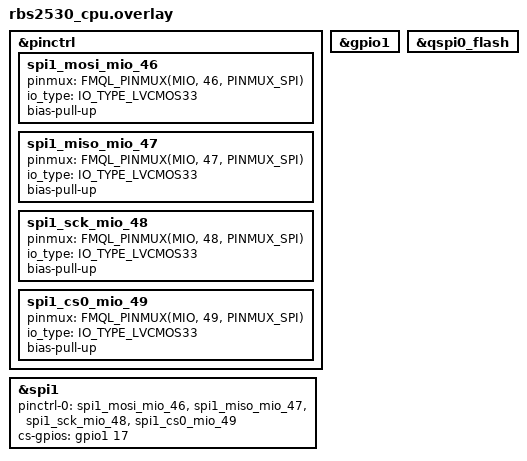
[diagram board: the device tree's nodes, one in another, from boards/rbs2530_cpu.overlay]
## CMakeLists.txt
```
# SPDX-License-Identifier: Apache-2.0

cmake_minimum_required(VERSION 3.20.0)

find_package(Zephyr REQUIRED HINTS $ENV{ZEPHYR_BASE})
project(security_shell)
target_include_directories(app PRIVATE inc)
target_sources(app PRIVATE src/main.c src/security_shell.c src/tpm_shell.c)
```

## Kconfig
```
# Copyright (c) 2025 SYSTech Co.
# SPDX-License-Identifier: Apache-2.0

mainmenu "security shell"
source "Kconfig.zephyr"
```

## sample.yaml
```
sample:
  description: rbs2530 security shell
  name: rbs2530 security shell
common:
  tags: app
tests:
  sample.rbs2530.rte.security_shell:
    tags: app
    extra_args:
      - CONFIG_COMPILER_WARNINGS_AS_ERRORS=n
    platform_allow:
      - rbs2530_cpu
```

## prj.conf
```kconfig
# Logging
CONFIG_LOG=y
CONFIG_LOG_MODE_IMMEDIATE=y
CONFIG_LOG_ALWAYS_RUNTIME=y
CONFIG_PRINTK=y

# Shell options
CONFIG_SHELL=y
CONFIG_SHELL_STACK_SIZE=16384
CONFIG_IDLE_STACK_SIZE=2048

# SSL options
CONFIG_WOLFSSL=y
CONFIG_WOLFSSL_BUILTIN=y
CONFIG_POSIX_THREADS=y
CONFIG_POSIX_API=n
CONFIG_TEST_RANDOM_GENERATOR=y
CONFIG_WOLFSSL_SETTINGS_FILE="inc/wolfssl_settings.h"

# Enable wolfTPM
CONFIG_WOLFTPM=y

# GmSSL minimal configuration for SM3 algorithm only
CONFIG_GMSSL=y
CONFIG_GMSSL_SDF=n
CONFIG_GMSSL_TLS=n
CONFIG_GMSSL_SHA1=n
CONFIG_GMSSL_SHA2=n
CONFIG_GMSSL_AES=n
CONFIG_GMSSL_CHACHA20=n
CONFIG_GMSSL_SM4_ECB=y
CONFIG_GMSSL_SM4_OFB=y
CONFIG_GMSSL_SM4_CFB=y
CONFIG_GMSSL_SM4_CCM=y
CONFIG_GMSSL_SM4_XTS=y
CONFIG_GMSSL_SM4_CBC_MAC=y
CONFIG_GMSSL_SM2_EXTS=n
CONFIG_GMSSL_SM3_XMSS=y

# Flash support
CONFIG_FLASH=y
CONFIG_GPIO=y
CONFIG_SPI=y
CONFIG_SPI_DW=y
CONFIG_SPI_DW_ACCESS_WORD_ONLY=y
CONFIG_SPI_NOR=y
CONFIG_SPI_NOR_FLASH_LAYOUT_PAGE_SIZE=256
CONFIG_SPI_NOR_SFDP_DEVICETREE=y

# 设备绑定支持
CONFIG_DEVICE_SHELL=y

# Generic kernel options
CONFIG_MAIN_STACK_SIZE=4096
CONFIG_HEAP_MEM_POOL_SIZE=26214400
CONFIG_COMMON_LIBC_MALLOC_ARENA_SIZE=26214400
```

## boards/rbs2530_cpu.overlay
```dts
&pinctrl {
	/omit-if-no-ref/ spi1_mosi_mio_46: spi1_mosi_mio_46 {
		pinmux = <FMQL_PINMUX(MIO, 46, PINMUX_SPI)>;
		io_type = <IO_TYPE_LVCMOS33>;
		bias-pull-up;
	};
	/omit-if-no-ref/ spi1_miso_mio_47: spi1_miso_mio_47 {
		pinmux = <FMQL_PINMUX(MIO, 47, PINMUX_SPI)>;
		io_type = <IO_TYPE_LVCMOS33>;
		bias-pull-up;
	};
	/omit-if-no-ref/ spi1_sck_mio_48: spi1_sck_mio_48 {
		pinmux = <FMQL_PINMUX(MIO, 48, PINMUX_SPI)>;
		io_type = <IO_TYPE_LVCMOS33>;
		bias-pull-up;
	};
	/omit-if-no-ref/ spi1_cs0_mio_49: spi1_cs0_mio_49 {
		pinmux = <FMQL_PINMUX(MIO, 49, PINMUX_SPI)>;
		io_type = <IO_TYPE_LVCMOS33>;
		bias-pull-up;
	};
};

&gpio1{
	status = "okay";
};

&spi1 {
	pinctrl-0 = <&spi1_mosi_mio_46>,
	<&spi1_miso_mio_47>,
	<&spi1_sck_mio_48>,
	<&spi1_cs0_mio_49>;
	pinctrl-names = "default";
	cs-gpios = <&gpio1 17 0>;
	status = "okay";
};

&qspi0_flash {
	status = "okay";
};
```

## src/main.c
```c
/**
 * @file main.c
 * @author Liao YuanKai(savent_gate@outlook.com)
 * @brief
 * @version 0.1
 * @date 2025-01-28
 *
 * @copyright Copyright (c) 2025 SYSTech Co.
 *
 */
#include <string.h>
#include <stdlib.h>
#include <zephyr/kernel.h>

#include "security_shell.h"

int main(void)
{
	while (1) {
		k_sleep(K_MSEC(1000));
	}
	return 0;
}
```

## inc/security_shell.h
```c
/**
 * @file security_shell.h
 * @author Liao YuanKai (savent_gate@outlook.com)
 * @brief
 * @version 0.1
 * @date 2025-05-06
 *
 * @copyright Copyright (c) 2025 SYSTech Co.
 *
 */
#pragma once

/* Global def/function prototypes */
```

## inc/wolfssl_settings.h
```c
/**
 * @file    wolfssl_settings.h
 * @brief   WolfSSL settings for Zephyr
 * @details This file contains the configuration settings for the WolfSSL library
 * @date   2025-05-09
 *
 * @copyright Copyright (c) 2025 SYSFly Co.
 *
 */
#pragma once

#ifdef __cplusplus
extern "C" {
#endif

#define ECC_TIMING_RESISTANT
#define WC_RSA_BLINDING

#define HAVE_ECC
#define WOLFSSL_PEM_TO_DER
#define WOLFSSL_DER_TO_PEM
#define WOLFSSL_KEY_GEN
#define WOLFSSL_CERT_GEN
#define WOLFSSL_CERT_REQ
#define WOLFSSL_PKCS512

#ifdef __cplusplus
}
#endif
```
